# LPC8N04 register map
File version: 0.1
CPU: CM0PLUS r0p0, little endian, no MPU, no FPU, 2 interrupt priority bits
Registers are 32-bit, read-write, no defined reset value unless marked. A register's access mark holds for its fields unless they carry their own. Offsets are from the block's base; [hi:lo] are bit positions.

## RTC — Real time clock timer
Base 0x40054000
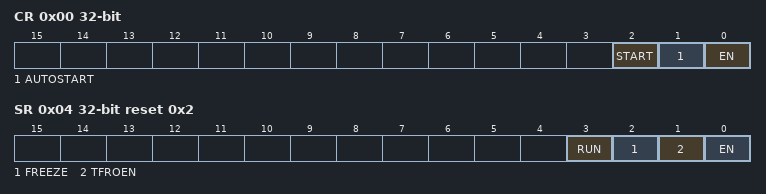
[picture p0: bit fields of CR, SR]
0x00 CR — RTC control register
  [2] START — Writing a 1 starts the countdown from the value stored in RTCSLEEPT until 0 is reached. Write 0 to clear. This bit is also cleared when the interrupt is asserted or a new value is written into the RTCSLEEPT register.
  [1] AUTOSTART — (1) Automatic timer start when value is written to RTCSLEEPT register, (0) manual start
  [0] EN — (1) Enable the RTC On/Off Timer, (0) disable
0x04 SR ro reset 0x2 (reset mask 0x0) — RTC status register
  [3] RUN — RTC timer is running
  [2] FREEZE — Asserted in the neighbourhood of edges on the internal tick clock. Values written to the RTCSLEEPT register during FREEZE=1 are delayed until after this conditions clears.
  [1] TFROEN — Timer oscillator input enabled (1) or disabled (0)
  [0] EN — RTC on/off timer enabled (1) or disabled (0)
0x08 CAL reset 0x8000 (reset mask 0x0) — RTC calibration value
  [15:0] CALIB — This value indicates the number of TFRO clock pulses in one tick.
0x0C SLEEPT — RTC Sleep time
  [23:0] SLEEPTIME — This value indicates the time to sleep in ticks.
0x10 VAL ro — Current RTC counter value
  [23:0] TIMEREMAIN — Current value (remaining time) of the countdown timer
0x14 IE — Interrupt mask register
  [0] IRQ — Software should set this bit to enable interrupt when the countdown is finished.
0x18 RIS ro — Raw Interrupt status register
  [0] RIS — This bit is 1 when the countdown has finished
0x1C MIS ro — Masked interrupt status register
  [0] MIS — This bit is 1 when the RTC countdown has finished and this interrupt is enabled.
0x20 IC wo — Interrupt clear register
  [0] IC — Writing a 1 clears the countdown done interrupt
0x24 STAT ro — Access status register
  [0] READY — (0) RTC access not possible, (1) RTC access possible
0x30 TIME — RTC Time register
  [31:0] TIME — Current timer value

## RFIDNFC — RFID and NFC
Base 0x40058000
0x00 CFG — RFID/NFC configuration register
  [0] EN — Enable RFID communication block. (1) Enable, (0) Disabled. When disabled, the block will not give access to the command registers or buffer memory space, and will not generate interrupts.
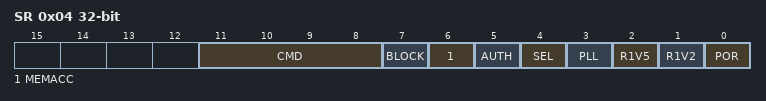
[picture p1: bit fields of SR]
0x04 SR ro — RFID/NFC status register
  [11:8] CMD — Last RFID command received
    0=REQA; 1=WUPA; 2=ANTICOLLISION; 3=SELECT; 4=HLTA; 5=READ; 6=COMP_WRITE; 7=WRITE; 8=INCR_CNT; 9=READ_CNT; 10=PWD_AUTH; 11=GET_VERSION; 12=FAST_READ; 13=READ_SIG; 15=CHECK_TEARING_EVENT
  [7] BLOCK — RFID buffer memory access by ARM was interrupted by RFID read/write action.
  [6] MEMACC — RFID buffer memory is being accessed by RF interface
  [5] AUTH — RFID password for access authenticated
  [4] SEL — RFID selected
  [3] PLL — RFID PLL locked
  [2] R1V5 — Rectifier less than 1.5 V output warning
  [1] R1V2 — Rectifier less than 1.2 V output warning
  [0] POR — Power-on detected in the RFID analog core
0x0C CMDIN ro — RFID/NFC incoming command
  [31:0] CMDIN — Incoming command
0x10 CMDOUT wo — RFID/NFC outgoing command
  [31:0] DATAOUT — Outgoing data
0x14 IE — Interrupt mask register
  [0] CMDIE — Set to 1 to enable interrupt when RFID READ/WRITE is detected
0x18 RIS ro — Raw Interrupt status register
  [0] CMD — RFID READ/WRITE access was detected
0x1C MIS ro — Masked interrupt status register
  [0] CMD — RFID READ/WRITE access was detected
0x20 IC wo — Interrupt clear register
  [0] CMDIC — Writing 1 clears the CMD interrupt

## TSEN — Temperature Sensor
Base 0x40060000
0x00 CR — Control register
  [0] START — sensor start bit. This bit is cleared by the temperature sensor at the end of the measurement.
0x04 DR ro — Data register. Contains result of conversion
  [15:0] DATA — Result of last conversion. Raw format is unsigned fixed point (0,5.11); calibrated format is signed (1, 9.6) 2-complement fixed point.
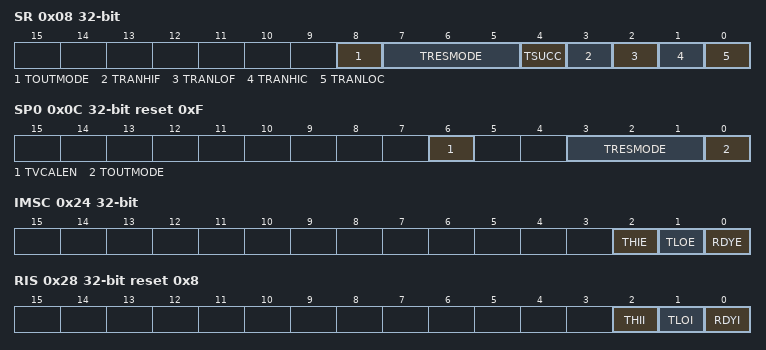
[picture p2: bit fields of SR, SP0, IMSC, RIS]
0x08 SR ro — Status register
  [8] TOUTMODE — used output mode
  [7:5] TRESMODE — used resolution mode
  [4] TSUCC — 1: successful conversion
  [3] TRANHIF — Fine range: 1: out of range (too large)
  [2] TRANLOF — Fine range: 1: out of range (too low)
  [1] TRANHIC — Coarse range: 1: out of range (too high)
  [0] TRANLOC — Coarse range: 1: out of range (too low)
0x0C SP0 reset 0xF (reset mask 0x0) — Setup register 0: set ADC and operation modes
  [6] TVCALEN — temperature sensor voltage calibration enable
  [3:1] TRESMODE — temperature sensor resolution mode. (0b010) 7 bit, (0b011) 8 bit, (0b100) 9 bit, (0b101) 10 bit, (0b110) 11 bits, (0b111) 12 bits (others not supported)
  [0] TOUTMODE — temperature sensor output mode. 0: raw data, 1: calibrated data
0x10 SP1 — Setup register 1: Calibration value ?A?
  [15:0] A — calibration factor ?A? unsigned fixed point (10.6)
0x14 SP2 — Setup register 2: Calibration value ?B?
  [15:0] B — calibration factor ?B? signed fixed point (10.6) 2-complement
0x18 SP3 — Setup register 3: Calibration value ?alpha?
  [15:0] ALPHA — calibration factor ?alpha? unsigned fixed point (6.10)
0x1C TLO — Low temperature threshold register
  [15:0] TLO — low-temperature threshold value in signed fixed point (10.6) 2-complement format.
0x20 THI — High temperature threshold register
  [15:0] THI — high-temperature threshold value in signed fixed point (10.6) 2-complement format.
0x24 IMSC — Interrupt Mask Set and Clear Register
  [2] THIE — Software should set this bit to enable interrupt when a temperature conversion is higher than the value stored in THI.
  [1] TLOE — Software should set this bit to enable interrupt when a temperature conversion is higher than the value stored in TLO.
  [0] RDYE — Software should set this bit to enable interrupt when a temperature conversion is ready on DR.
0x28 RIS ro reset 0x8 (reset mask 0x0) — Raw Interrupt Status Register
  [2] THII — This bit is 1 when a temperature conversion has finished and the value exceeds the threshold value set in the THI register
  [1] TLOI — This bit is 1 when a temperature conversion has finished and the value is below the threshold value set in the TLO register
  [0] RDYI — This bit is 1 when a temperature conversion has finished
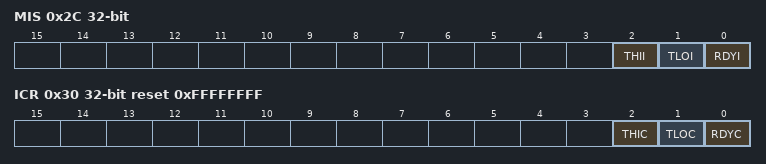
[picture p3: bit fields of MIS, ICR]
0x2C MIS ro — Masked Interrupt Status Register
  [2] THII — This bit is 1 when a temperature conversion has finished, if the value exceeds the threshold value set in the THI register, and this interrupt is enabled
  [1] TLOI — This bit is 1 when a temperature conversion has finished, if the value is below the threshold value set in the TLO register and this interrupt is enabled.
  [0] RDYI — This bit is 1 when a temperature conversion has finished and this interrupt is enabled.
0x30 ICR wo reset 0xFFFFFFFF (reset mask 0x0) — Interrupt Clear Register
  [2] THIC — Writing a 1 clears the temperature sensor high threshold interrupt
  [1] TLOC — Writing a 1 clears the temperature sensor low threshold interrupt
  [0] RDYC — Writing a 1 clears the temperature sensor conversion ready interrupt

## GPIO — General Purpose IO
Base 0x50008000
0x00 DIR — Data direction register
  [11:0] IO — Selects pin x as input or output (x = 0 to 11). 0 = Pin PIOn_x is configured as input. 1 = Pin PIOn_x is configured as output.
0x04 IS — Interrupt sense register
  [11:0] ISENSE — Selects interrupt on pin x as level or edge sensitive (x = 0 to11). 0 = Interrupt on pin PIOn_x is configured as edge sensitive. 1 = Interrupt on pin PIOn_x is configured as level sensitive.
0x08 IBE — Interrupt both edges register
  [11:0] IBE — Selects interrupt on pin x to be triggered on both edges (x = 0 to 11). 0 = Interrupt on pin PIO_x is controlled through register GPIOIEV. 1 = Both edges on pin PIO_x trigger an interrupt.
0x0C IEV — Interrupt event register
  [11:0] IEV — Selects interrupt on pin x to be triggered rising or falling edges (x = 0 to 11). 0 = Depending on setting in register GPIOIS, falling edges or LOW level on pin PIO_x trigger an interrupt. 1 = Depending on setting in register GPIOIS, rising edges or HIGH level on pin PIO_x trigger an interrupt.
0x10 IE — Interrupt mask register
  [11:0] MASK — Selects interrupt on pin x to be masked (x = 0 to 11). 0 = Interrupt on pin PIO_x is masked. 1 = Interrupt on pin PIO_x is not masked.
0x14 RIS ro — Raw Interrupt status register
  [11:0] RAWST — Raw interrupt status (x = 0 to 11). 0 = No interrupt on pin PIO_x. 1 = Interrupt requirements met on PIO_x.
0x18 MIS ro — Masked interrupt status register
  [11:0] MASK — Selects interrupt on pin x to be masked (x = 0 to 11). 0 = No interrupt or interrupt masked on pin PIO_x. 1 = Interrupt on PIO_x.
0x1C IC wo — Interrupt clear register
  [11:0] CLR — Selects interrupt on pin x to be cleared (x = 0 to 11). Clears the interrupt edge detection logic. This register is write-only. Remark: The synchronizer between the GPIO and the NVIC blocks causes a delay of 2 clocks. It is recommended to add two NOPs after the clear of the interrupt edge detection logic before the exit of the interrupt service routine. 0 = No effect. 1 = Clears edge detection logic for pin PIO_x.
